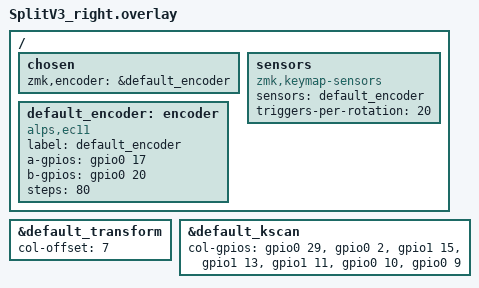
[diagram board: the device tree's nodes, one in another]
#include  "SplitV3.dtsi"

/ {
    chosen {
        zmk,encoder = &default_encoder;
    };

    sensors{
        compatible = "zmk,keymap-sensors";
        sensors = <&default_encoder>;
        triggers-per-rotation = <20>;
    };

    default_encoder: encoder{
        compatible = "alps,ec11";
        label = "default_encoder";
        a-gpios = <&gpio0 17 (GPIO_ACTIVE_HIGH | GPIO_PULL_UP)>;
        b-gpios = <&gpio0 20 (GPIO_ACTIVE_HIGH | GPIO_PULL_UP)>;
        steps = <80>;
        status = "okay";
    };
};


&default_transform {
    col-offset = <7>;
};

&default_kscan {
        col-gpios = <&gpio0 29 (GPIO_ACTIVE_HIGH)>,
                    <&gpio0 2 (GPIO_ACTIVE_HIGH)>,
                    <&gpio1 15 (GPIO_ACTIVE_HIGH)>,
                    <&gpio1 13 (GPIO_ACTIVE_HIGH)>,
                    <&gpio1 11 (GPIO_ACTIVE_HIGH)>,
                    <&gpio0 10 (GPIO_ACTIVE_HIGH)>,
                    <&gpio0 9  (GPIO_ACTIVE_HIGH)>;
    };
